# STM32N645 register map
File version: 1.0
CPU: CM55 r0p1, little endian, no MPU, FPU, vendor SysTick, 8 interrupt priority bits
Registers are 32-bit, read-write, reset 0x0 unless marked. A register's access mark holds for its fields unless they carry their own. Offsets are from the block's base; [hi:lo] are bit positions; {n}, {i} and the like mark numbered series; 'fields as' and 'values as' point back to an identical list.

## OTG1 — USB on-the-go high-speed
Base 0x48040000
Same registers: OTG2 0x48080000, OTG1_S 0x58040000, OTG2_S 0x58080000
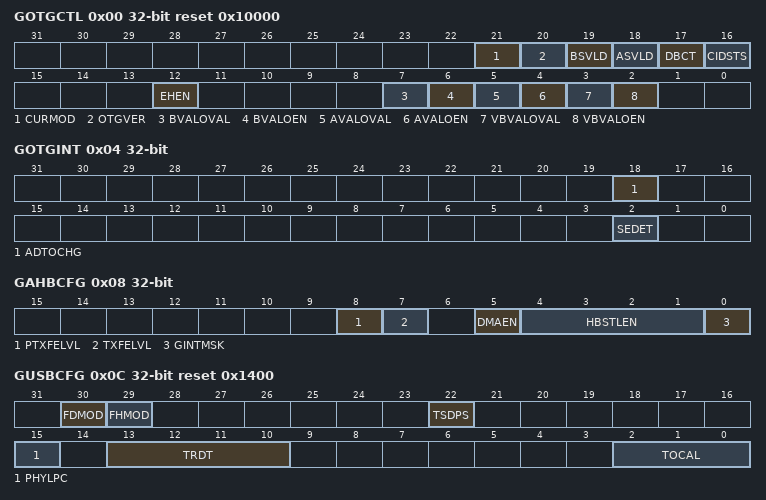
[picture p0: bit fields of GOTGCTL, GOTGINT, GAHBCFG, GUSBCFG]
0x00 GOTGCTL access per field reset 0x10000 — OTG control and status register
  [21] CURMOD ro — Current mode of operation
  [20] OTGVER rw — OTG version
  [19] BSVLD ro — B-session valid
  [18] ASVLD ro — A-session valid
  [17] DBCT ro — Long/short debounce time
  [16] CIDSTS ro — Connector ID status
  [12] EHEN rw — Embedded host enable
  [7] BVALOVAL rw — B-peripheral session valid override value.
  [6] BVALOEN rw — B-peripheral session valid override enable.
  [5] AVALOVAL rw — A-peripheral session valid override value.
  [4] AVALOEN rw — A-peripheral session valid override enable.
  [3] VBVALOVAL rw — V less than sub>BUS less than /sub> valid override value.
  [2] VBVALOEN rw — V less than sub>BUS less than /sub> valid override enable.
0x04 GOTGINT — OTG interrupt register
  [18] ADTOCHG — A-device timeout change
  [2] SEDET — Session end detected
0x08 GAHBCFG — OTG AHB configuration register
  [8] PTXFELVL — Periodic Tx FIFO empty level
  [7] TXFELVL — Tx FIFO empty level
  [5] DMAEN — DMA enabled
  [4:1] HBSTLEN — Burst length/type
  [0] GINTMSK — Global interrupt mask
0x0C GUSBCFG reset 0x1400 — OTG USB configuration register
  [30] FDMOD — Force device mode
  [29] FHMOD — Force host mode
  [22] TSDPS — TermSel DLine pulsing selection
  [15] PHYLPC — PHY Low-power clock select
  [13:10] TRDT — USB turnaround time
  [2:0] TOCAL — FS timeout calibration
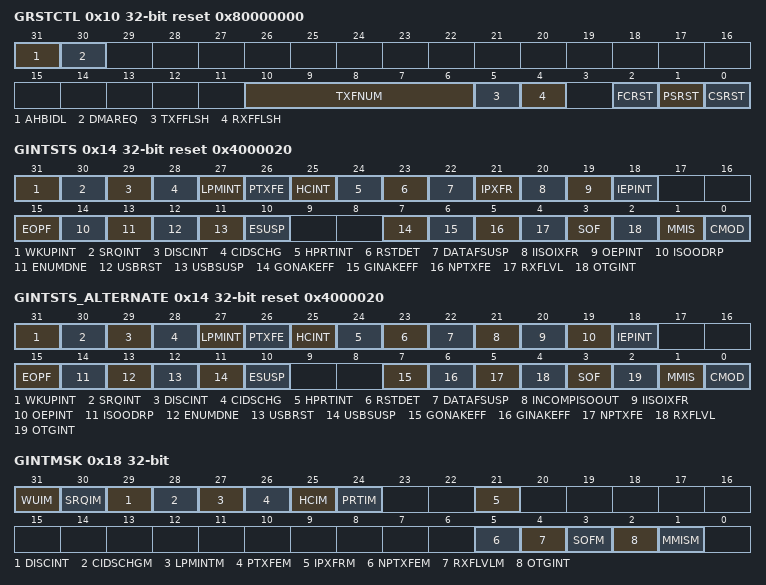
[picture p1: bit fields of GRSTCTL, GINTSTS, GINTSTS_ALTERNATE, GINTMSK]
0x10 GRSTCTL access per field reset 0x80000000 — OTG reset register
  [31] AHBIDL ro — AHB master idle
  [30] DMAREQ ro — DMA request signal enabled
  [10:6] TXFNUM rw — Tx FIFO number
  [5] TXFFLSH rw — Tx FIFO flush
  [4] RXFFLSH rw — Rx FIFO flush
  [2] FCRST rw — Host frame counter reset
  [1] PSRST rw — Partial soft reset
  [0] CSRST rw — Core soft reset
0x14 GINTSTS access per field reset 0x4000020 — OTG core interrupt register [alternate]
  [31] WKUPINT rw — Resume/remote wake-up detected interrupt
  [30] SRQINT rw — Session request/new session detected interrupt
  [29] DISCINT rw — Disconnect detected interrupt
  [28] CIDSCHG rw — Connector ID status change
  [27] LPMINT rw — LPM interrupt
  [26] PTXFE ro — Periodic Tx FIFO empty
  [25] HCINT ro — Host channels interrupt
  [24] HPRTINT ro — Host port interrupt
  [23] RSTDET rw — Reset detected interrupt
  [22] DATAFSUSP rw — Data fetch suspended
  [21] IPXFR rw — Incomplete periodic transfer
  [20] IISOIXFR rw — Incomplete isochronous IN transfer
  [19] OEPINT ro — OUT endpoint interrupt
  [18] IEPINT ro — IN endpoint interrupt
  [15] EOPF rw — End of periodic frame interrupt
  [14] ISOODRP rw — Isochronous OUT packet dropped interrupt
  [13] ENUMDNE rw — Enumeration done
  [12] USBRST rw — USB reset
  [11] USBSUSP rw — USB suspend
  [10] ESUSP rw — Early suspend
  [7] GONAKEFF ro — Global OUT NAK effective
  [6] GINAKEFF ro — Global IN non-periodic NAK effective
  [5] NPTXFE ro — Non-periodic Tx FIFO empty
  [4] RXFLVL ro — Rx FIFO non-empty
  [3] SOF rw — Start of frame
  [2] OTGINT ro — OTG interrupt
  [1] MMIS rw — Mode mismatch interrupt
  [0] CMOD ro — Current mode of operation
0x14 GINTSTS_ALTERNATE access per field reset 0x4000020 (alternate view of GINTSTS) — OTG core interrupt register [alternate]
  [31] WKUPINT rw — Resume/remote wake-up detected interrupt
  [30] SRQINT rw — Session request/new session detected interrupt
  [29] DISCINT rw — Disconnect detected interrupt
  [28] CIDSCHG rw — Connector ID status change
  [27] LPMINT rw — LPM interrupt
  [26] PTXFE ro — Periodic Tx FIFO empty
  [25] HCINT ro — Host channels interrupt
  [24] HPRTINT ro — Host port interrupt
  [23] RSTDET rw — Reset detected interrupt
  [22] DATAFSUSP rw — Data fetch suspended
  [21] INCOMPISOOUT rw — Incomplete isochronous OUT transfer
  [20] IISOIXFR rw — Incomplete isochronous IN transfer
  [19] OEPINT ro — OUT endpoint interrupt
  [18] IEPINT ro — IN endpoint interrupt
  [15] EOPF rw — End of periodic frame interrupt
  [14] ISOODRP rw — Isochronous OUT packet dropped interrupt
  [13] ENUMDNE rw — Enumeration done
  [12] USBRST rw — USB reset
  [11] USBSUSP rw — USB suspend
  [10] ESUSP rw — Early suspend
  [7] GONAKEFF ro — Global OUT NAK effective
  [6] GINAKEFF ro — Global IN non-periodic NAK effective
  [5] NPTXFE ro — Non-periodic Tx FIFO empty
  [4] RXFLVL ro — Rx FIFO non-empty
  [3] SOF rw — Start of frame
  [2] OTGINT ro — OTG interrupt
  [1] MMIS rw — Mode mismatch interrupt
  [0] CMOD ro — Current mode of operation
0x18 GINTMSK access per field — OTG interrupt mask register [alternate]
  [31] WUIM rw — Resume/remote wake-up detected interrupt mask
  [30] SRQIM rw — Session request/new session detected interrupt mask
  [29] DISCINT rw — Disconnect detected interrupt mask
  [28] CIDSCHGM rw — Connector ID status change mask
  [27] LPMINTM rw — LPM interrupt mask
  [26] PTXFEM rw — Periodic Tx FIFO empty mask
  [25] HCIM rw — Host channels interrupt mask
  [24] PRTIM ro — Host port interrupt mask
  [21] IPXFRM rw — Incomplete periodic transfer mask
  [5] NPTXFEM rw — Non-periodic Tx FIFO empty mask
  [4] RXFLVLM rw — Receive FIFO non-empty mask
  [3] SOFM rw — Start of frame mask
  [2] OTGINT rw — OTG interrupt mask
  [1] MMISM rw — Mode mismatch interrupt mask
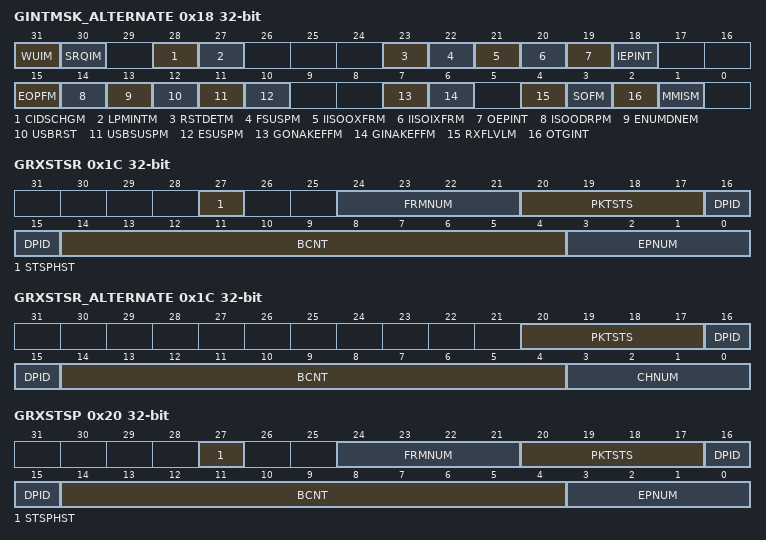
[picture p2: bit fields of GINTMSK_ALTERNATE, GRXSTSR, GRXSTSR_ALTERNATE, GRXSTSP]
0x18 GINTMSK_ALTERNATE (alternate view of GINTMSK) — OTG interrupt mask register [alternate]
  [31] WUIM — Resume/remote wake-up detected interrupt mask
  [30] SRQIM — Session request/new session detected interrupt mask
  [28] CIDSCHGM — Connector ID status change mask
  [27] LPMINTM — LPM interrupt mask
  [23] RSTDETM — Reset detected interrupt mask
  [22] FSUSPM — Data fetch suspended mask
  [21] IISOOXFRM — Incomplete isochronous OUT transfer mask
  [20] IISOIXFRM — Incomplete isochronous IN transfer mask
  [19] OEPINT — OUT endpoints interrupt mask
  [18] IEPINT — IN endpoints interrupt mask
  [15] EOPFM — End of periodic frame interrupt mask
  [14] ISOODRPM — Isochronous OUT packet dropped interrupt mask
  [13] ENUMDNEM — Enumeration done mask
  [12] USBRST — USB reset mask
  [11] USBSUSPM — USB suspend mask
  [10] ESUSPM — Early suspend mask
  [7] GONAKEFFM — Global OUT NAK effective mask
  [6] GINAKEFFM — Global non-periodic IN NAK effective mask
  [4] RXFLVLM — Receive FIFO non-empty mask
  [3] SOFM — Start of frame mask
  [2] OTGINT — OTG interrupt mask
  [1] MMISM — Mode mismatch interrupt mask
0x1C GRXSTSR ro — OTG receive status debug read register [alternate]
  [27] STSPHST — Status phase start
  [24:21] FRMNUM — Frame number
  [20:17] PKTSTS — Packet status
  [16:15] DPID — Data PID
  [14:4] BCNT — Byte count
  [3:0] EPNUM — Endpoint number
0x1C GRXSTSR_ALTERNATE ro (alternate view of GRXSTSR) — OTG receive status debug read register [alternate]
  [20:17] PKTSTS — Packet status
  [16:15] DPID — Data PID
  [14:4] BCNT — Byte count
  [3:0] CHNUM — Channel number
0x20 GRXSTSP ro — OTG status read and pop registers
  fields as GRXSTSR
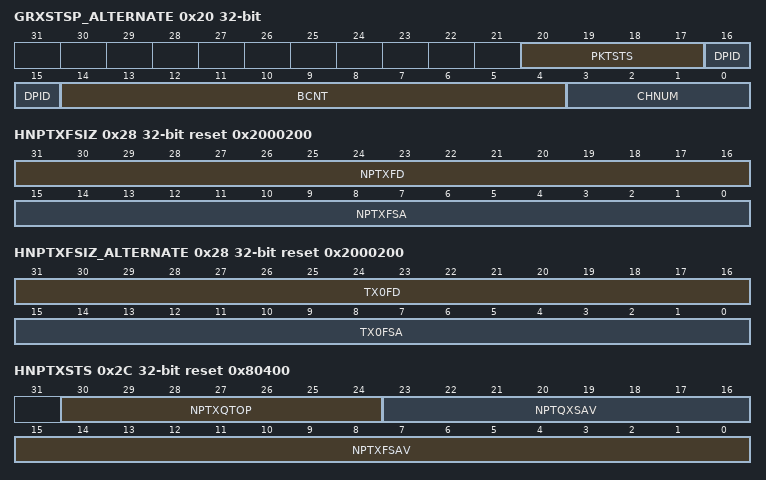
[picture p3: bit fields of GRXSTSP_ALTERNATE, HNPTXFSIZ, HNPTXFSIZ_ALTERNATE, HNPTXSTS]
0x20 GRXSTSP_ALTERNATE ro (alternate view of GRXSTSP) — OTG status read and pop registers
  fields as GRXSTSR_ALTERNATE
0x24 GRXFSIZ reset 0x400 — OTG receive FIFO size register
  [15:0] RXFD — Rx FIFO depth
0x28 HNPTXFSIZ reset 0x2000200 — OTG host non-periodic transmit FIFO size register [alternate]
  [31:16] NPTXFD — Non-periodic Tx FIFO depth
  [15:0] NPTXFSA — Non-periodic transmit RAM start address
0x28 HNPTXFSIZ_ALTERNATE reset 0x2000200 (alternate view of HNPTXFSIZ) — OTG host non-periodic transmit FIFO size register [alternate]
  [31:16] TX0FD — Endpoint 0 Tx FIFO depth
  [15:0] TX0FSA — Endpoint 0 transmit RAM start address
0x2C HNPTXSTS ro reset 0x80400 — OTG non-periodic transmit FIFO/queue status register
  [30:24] NPTXQTOP — Top of the non-periodic transmit request queue
  [23:16] NPTQXSAV — Non-periodic transmit request queue space available
  [15:0] NPTXFSAV — Non-periodic Tx FIFO space available
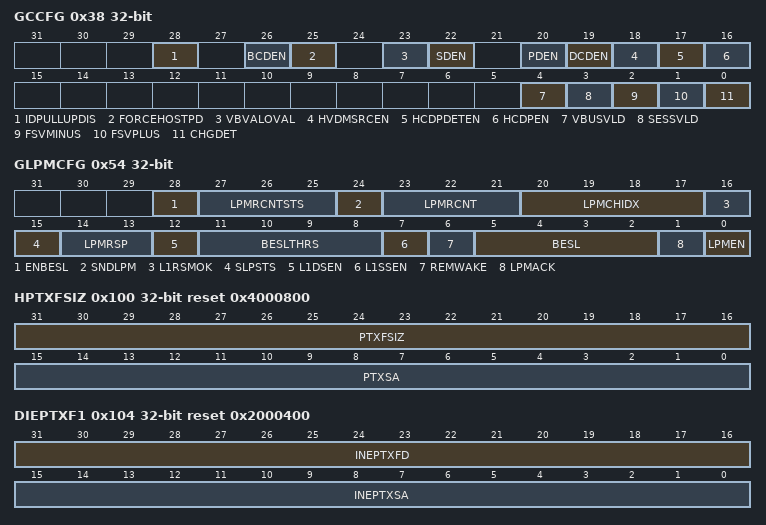
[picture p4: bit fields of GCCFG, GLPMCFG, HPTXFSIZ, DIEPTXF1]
0x38 GCCFG access per field (reset mask 0xFFFF0000) — OTG general core configuration register
  [28] IDPULLUPDIS rw — Disable ID pin pull-up
  [26] BCDEN rw — Force Battery charging (BC) mode
  [25] FORCEHOSTPD rw — Force host mode pull-downs
  [23] VBVALOVAL rw — Software override value of the VBUS B-session detection
  [22] SDEN rw — Secondary detection enable
  [20] PDEN rw — Primary detection enable
  [19] DCDEN rw — Data Contact Detection enable
  [18] HVDMSRCEN rw — Host CDP port Voltage source enable on DM
  [17] HCDPDETEN rw — Host CDP port voltage detector enable on DP
  [16] HCDPEN rw — Host CDP behavior enable
  [4] VBUSVLD ro — VBUS valid indicator
  [3] SESSVLD ro — VBUS session indicator
  [2] FSVMINUS ro — Single-Ended DM indicator
  [1] FSVPLUS ro — Single-Ended DP indicator
  [0] CHGDET ro — Charger detection, result of the current mode (primary or secondary).
0x3C CID reset 0x5000 — OTG core ID register
  [31:0] PRODUCT_ID
0x54 GLPMCFG access per field — OTG core LPM configuration register
  [28] ENBESL rw — Enable best effort service latency
  [27:25] LPMRCNTSTS ro — LPM retry count status
  [24] SNDLPM rw — Send LPM transaction
  [23:21] LPMRCNT rw — LPM retry count
  [20:17] LPMCHIDX rw — LPM Channel Index
  [16] L1RSMOK ro — Sleep state resume OK
  [15] SLPSTS ro — Port sleep status
  [14:13] LPMRSP ro — LPM response
  [12] L1DSEN rw — L1 deep sleep enable
  [11:8] BESLTHRS rw — BESL threshold
  [7] L1SSEN rw — L1 Shallow Sleep enable
  [6] REMWAKE rw — bRemoteWake value
  [5:2] BESL rw — Best effort service latency
  [1] LPMACK rw — LPM token acknowledge enable
  [0] LPMEN rw — LPM support enable
0x100 HPTXFSIZ reset 0x4000800 — OTG host periodic transmit FIFO size register
  [31:16] PTXFSIZ — Host periodic Tx FIFO depth
  [15:0] PTXSA — Host periodic Tx FIFO start address
0x104 DIEPTXF1 reset 0x2000400 — OTG device IN endpoint transmit FIFO 1 size register
  [31:16] INEPTXFD — IN endpoint Tx FIFO depth
  [15:0] INEPTXSA — IN endpoint FIFOx transmit RAM start address
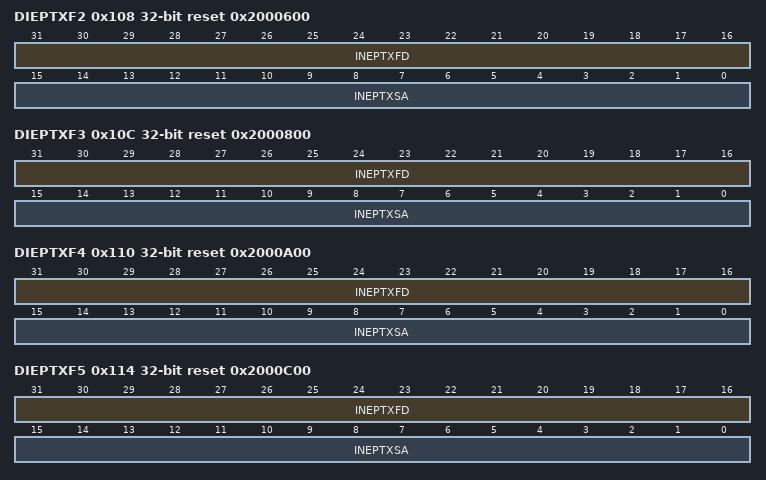
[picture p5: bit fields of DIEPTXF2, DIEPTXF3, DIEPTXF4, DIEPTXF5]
0x108 DIEPTXF2 reset 0x2000600 — OTG device IN endpoint transmit FIFO 2 size register
  fields as DIEPTXF1
0x10C DIEPTXF3 reset 0x2000800 — OTG device IN endpoint transmit FIFO 3 size register
  fields as DIEPTXF1
0x110 DIEPTXF4 reset 0x2000A00 — OTG device IN endpoint transmit FIFO 4 size register
  fields as DIEPTXF1
0x114 DIEPTXF5 reset 0x2000C00 — OTG device IN endpoint transmit FIFO 5 size register
  fields as DIEPTXF1
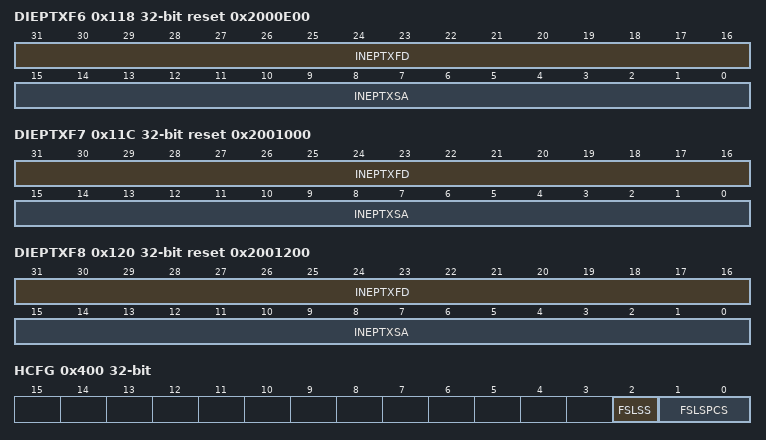
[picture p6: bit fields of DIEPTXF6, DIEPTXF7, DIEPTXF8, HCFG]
0x118 DIEPTXF6 reset 0x2000E00 — OTG device IN endpoint transmit FIFO 6 size register
  fields as DIEPTXF1
0x11C DIEPTXF7 reset 0x2001000 — OTG device IN endpoint transmit FIFO 7 size register
  fields as DIEPTXF1
0x120 DIEPTXF8 reset 0x2001200 — OTG device IN endpoint transmit FIFO 8 size register
  fields as DIEPTXF1
0x400 HCFG access per field — OTG host configuration register
  [2] FSLSS ro — FS- and LS-only support
  [1:0] FSLSPCS rw — FS/LS PHY clock select
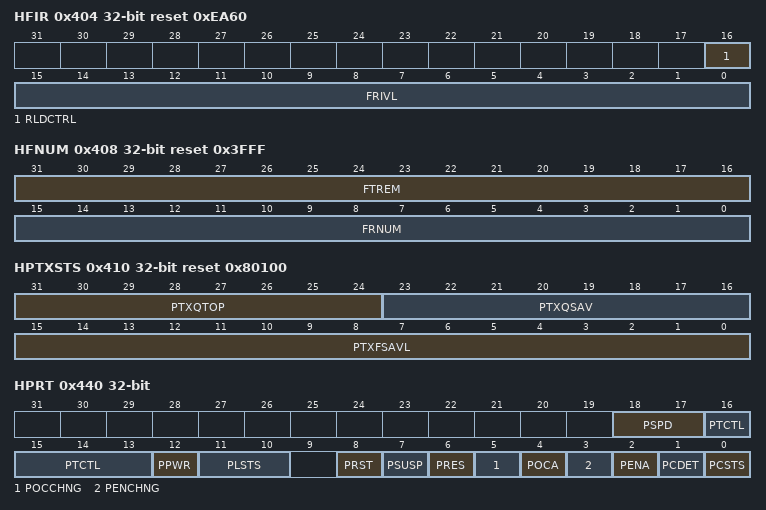
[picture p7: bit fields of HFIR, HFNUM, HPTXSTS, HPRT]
0x404 HFIR reset 0xEA60 — OTG host frame interval register
  [16] RLDCTRL — Reload control
  [15:0] FRIVL — Frame interval
0x408 HFNUM ro reset 0x3FFF — OTG host frame number/frame time remaining register
  [31:16] FTREM — Frame time remaining
  [15:0] FRNUM — Frame number
0x410 HPTXSTS ro reset 0x80100 — OTG_Host periodic transmit FIFO/queue status register
  [31:24] PTXQTOP — Top of the periodic transmit request queue
  [23:16] PTXQSAV — Periodic transmit request queue space available
  [15:0] PTXFSAVL — Periodic transmit data FIFO space available
0x414 HAINT ro — OTG host all channels interrupt register
  [15:0] HAINT — Channel interrupts
0x418 HAINTMSK — OTG host all channels interrupt mask register
  [15:0] HAINTM — Channel interrupt mask
0x440 HPRT access per field — OTG host port control and status register
  [18:17] PSPD ro — Port speed
  [16:13] PTCTL rw — Port test control
  [12] PPWR rw — Port power
  [11:10] PLSTS ro — Port line status
  [8] PRST rw — Port reset
  [7] PSUSP rw — Port suspend
  [6] PRES rw — Port resume
  [5] POCCHNG rw — Port overcurrent change
  [4] POCA ro — Port overcurrent active
  [3] PENCHNG rw — Port enable/disable change
  [2] PENA rw — Port enable
  [1] PCDET rw — Port connect detected
  [0] PCSTS ro — Port connect status
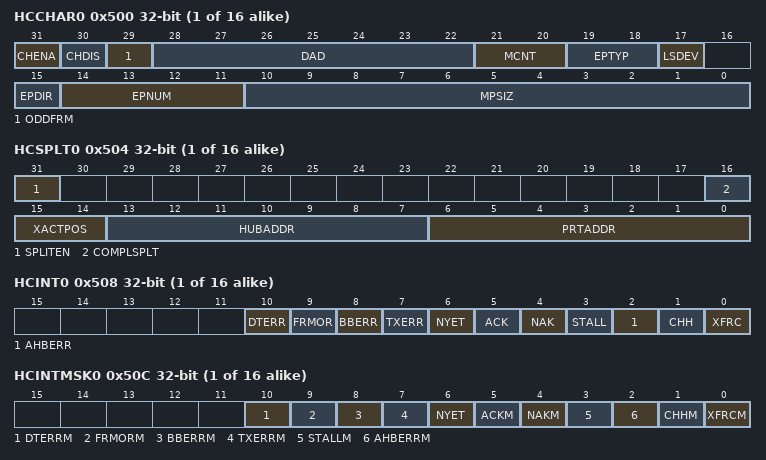
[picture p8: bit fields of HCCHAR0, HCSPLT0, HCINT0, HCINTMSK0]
{0x500+0x20*i} HCCHAR{i} (i=0..15) — OTG host channel {i} characteristics register
  [31] CHENA — Channel enable
  [30] CHDIS — Channel disable
  [29] ODDFRM — Odd frame
  [28:22] DAD — Device address
  [21:20] MCNT — Multicount
  [19:18] EPTYP — Endpoint type
  [17] LSDEV — Low-speed device
  [15] EPDIR — Endpoint direction
  [14:11] EPNUM — Endpoint number
  [10:0] MPSIZ — Maximum packet size
{0x504+0x20*i} HCSPLT{i} (i=0..15) — OTG host channel {i} split control register
  [31] SPLITEN — Split enable
  [16] COMPLSPLT — Do complete split
  [15:14] XACTPOS — Transaction position
  [13:7] HUBADDR — Hub address
  [6:0] PRTADDR — Port address
{0x508+0x20*i} HCINT{i} (i=0..15) — OTG host channel {i} interrupt register
  [10] DTERR — Data toggle error.
  [9] FRMOR — Frame overrun.
  [8] BBERR — Babble error.
  [7] TXERR — Transaction error.
  [6] NYET — Not yet ready response received interrupt.
  [5] ACK — ACK response received/transmitted interrupt.
  [4] NAK — NAK response received interrupt.
  [3] STALL — STALL response received interrupt.
  [2] AHBERR — AHB error
  [1] CHH — Channel halted.
  [0] XFRC — Transfer completed.
{0x50C+0x20*i} HCINTMSK{i} (i=0..15) — OTG host channel {i} interrupt mask register
  [10] DTERRM — Data toggle error mask.
  [9] FRMORM — Frame overrun mask.
  [8] BBERRM — Babble error mask.
  [7] TXERRM — Transaction error mask.
  [6] NYET — response received interrupt mask.
  [5] ACKM — ACK response received/transmitted interrupt mask.
  [4] NAKM — NAK response received interrupt mask.
  [3] STALLM — STALL response received interrupt mask.
  [2] AHBERRM — AHB error.
  [1] CHHM — Channel halted mask
  [0] XFRCM — Transfer completed mask
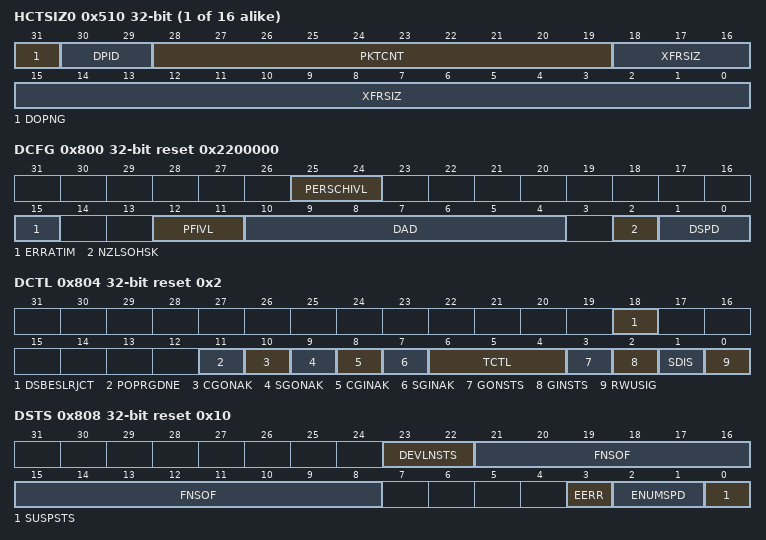
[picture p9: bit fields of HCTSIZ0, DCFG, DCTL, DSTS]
{0x510+0x20*i} HCTSIZ{i} (i=0..15) — OTG host channel {i} transfer size register
  [31] DOPNG — Do Ping
  [30:29] DPID — Data PID
  [28:19] PKTCNT — Packet count
  [18:0] XFRSIZ — Transfer size
{0x514+0x20*i} HCDMA{i} (i=0..15) — OTG host channel {i} DMA address register
  [31:0] DMAADDR — DMA address
0x800 DCFG reset 0x2200000 — OTG device configuration register
  [25:24] PERSCHIVL — Periodic schedule interval
  [15] ERRATIM — Erratic error interrupt mask
  [12:11] PFIVL — Periodic frame interval
  [10:4] DAD — Device address
  [2] NZLSOHSK — Non-zero-length status OUT handshake
  [1:0] DSPD — Device speed
0x804 DCTL access per field reset 0x2 — OTG device control register
  [18] DSBESLRJCT rw — Deep sleep BESL reject
  [11] POPRGDNE rw — Power-on programming done
  [10] CGONAK wo — Clear global OUT NAK
  [9] SGONAK wo — Set global OUT NAK
  [8] CGINAK wo — Clear global IN NAK
  [7] SGINAK wo — Set global IN NAK
  [6:4] TCTL rw — Test control
  [3] GONSTS ro — Global OUT NAK status
  [2] GINSTS ro — Global IN NAK status
  [1] SDIS rw — Soft disconnect
  [0] RWUSIG rw — Remote wake-up signaling
0x808 DSTS ro reset 0x10 — OTG device status register
  [23:22] DEVLNSTS — Device line status
  [21:8] FNSOF — Frame number of the received SOF
  [3] EERR — Erratic error
  [2:1] ENUMSPD — Enumerated speed
  [0] SUSPSTS — Suspend status
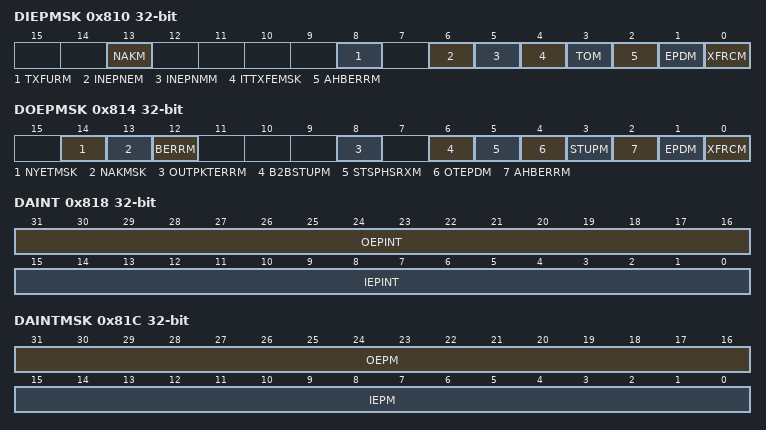
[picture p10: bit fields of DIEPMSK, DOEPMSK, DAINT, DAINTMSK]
0x810 DIEPMSK — OTG device IN endpoint common interrupt mask register
  [13] NAKM — NAK interrupt mask
  [8] TXFURM — FIFO underrun mask
  [6] INEPNEM — IN endpoint NAK effective mask
  [5] INEPNMM — IN token received with EP mismatch mask
  [4] ITTXFEMSK — IN token received when Tx FIFO empty mask
  [3] TOM — Timeout condition mask (Non-isochronous endpoints)
  [2] AHBERRM — AHB error mask
  [1] EPDM — Endpoint disabled interrupt mask
  [0] XFRCM — Transfer completed interrupt mask
0x814 DOEPMSK — OTG device OUT endpoint common interrupt mask register
  [14] NYETMSK — NYET interrupt mask
  [13] NAKMSK — NAK interrupt mask
  [12] BERRM — Babble error interrupt mask
  [8] OUTPKTERRM — Out packet error mask
  [6] B2BSTUPM — Back-to-back SETUP packets received mask
  [5] STSPHSRXM — Status phase received for control write mask
  [4] OTEPDM — OUT token received when endpoint disabled mask. Applies to control OUT endpoints only.
  [3] STUPM — STUPM: SETUP phase done mask. Applies to control endpoints only.
  [2] AHBERRM — AHB error mask
  [1] EPDM — Endpoint disabled interrupt mask
  [0] XFRCM — Transfer completed interrupt mask
0x818 DAINT ro — OTG device all endpoints interrupt register
  [31:16] OEPINT — OUT endpoint interrupt bits
  [15:0] IEPINT — IN endpoint interrupt bits
0x81C DAINTMSK — OTG all endpoints interrupt mask register
  [31:16] OEPM — OUT EP interrupt mask bits
  [15:0] IEPM — IN EP interrupt mask bits
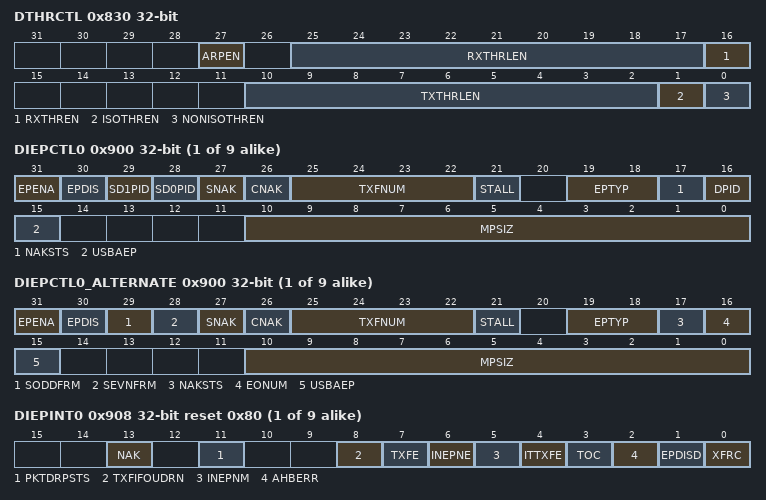
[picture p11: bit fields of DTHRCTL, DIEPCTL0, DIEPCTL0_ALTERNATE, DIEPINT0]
0x830 DTHRCTL — OTG device threshold control register
  [27] ARPEN — Arbiter parking enable
  [25:17] RXTHRLEN — Receive threshold length
  [16] RXTHREN — Receive threshold enable
  [10:2] TXTHRLEN — Transmit threshold length
  [1] ISOTHREN — ISO IN endpoint threshold enable
  [0] NONISOTHREN — Nonisochronous IN endpoints threshold enable
0x834 DIEPEMPMSK — OTG device IN endpoint FIFO empty interrupt mask register
  [15:0] INEPTXFEM — IN EP Tx FIFO empty interrupt mask bits
{0x900+0x20*i} DIEPCTL{i} access per field (i=0..8) — OTG device IN endpoint {i} control register [alternate]
  [31] EPENA rw — Endpoint enable
  [30] EPDIS rw — Endpoint disable
  [29] SD1PID wo — Set DATA1 PID
  [28] SD0PID wo — Set DATA0 PID
  [27] SNAK wo — Set NAK
  [26] CNAK wo — Clear NAK
  [25:22] TXFNUM rw — Tx FIFO number
  [21] STALL rw — STALL handshake
  [19:18] EPTYP rw — Endpoint type
  [17] NAKSTS ro — NAK status
  [16] DPID ro — Endpoint data PID
  [15] USBAEP rw — USB active endpoint
  [10:0] MPSIZ rw — Maximum packet size
{0x900+0x20*i} DIEPCTL{i}_ALTERNATE access per field (alternate view of DIEPCTL{i}) (i=0..8) — OTG device IN endpoint {i} control register [alternate]
  [31] EPENA rw — Endpoint enable
  [30] EPDIS rw — Endpoint disable
  [29] SODDFRM wo — Set odd frame
  [28] SEVNFRM wo — Set even frame
  [27] SNAK wo — Set NAK
  [26] CNAK wo — Clear NAK
  [25:22] TXFNUM rw — Tx FIFO number
  [21] STALL rw — STALL handshake
  [19:18] EPTYP rw — Endpoint type
  [17] NAKSTS ro — NAK status
  [16] EONUM ro — Even/odd frame
  [15] USBAEP rw — USB active endpoint
  [10:0] MPSIZ rw — Maximum packet size
{0x908+0x20*i} DIEPINT{i} access per field reset 0x80 (i=0..8) — OTG device IN endpoint {i} interrupt register
  [13] NAK rw — NAK input
  [11] PKTDRPSTS rw — Packet dropped status
  [8] TXFIFOUDRN rw — Transmit Fifo Underrun (TxfifoUndrn)
  [7] TXFE ro — Transmit FIFO empty
  [6] INEPNE rw — IN endpoint NAK effective
  [5] INEPNM rw — IN token received with EP mismatch
  [4] ITTXFE rw — IN token received when Tx FIFO is empty
  [3] TOC rw — Timeout condition
  [2] AHBERR rw — AHB error
  [1] EPDISD rw — Endpoint disabled interrupt
  [0] XFRC rw — Transfer completed interrupt
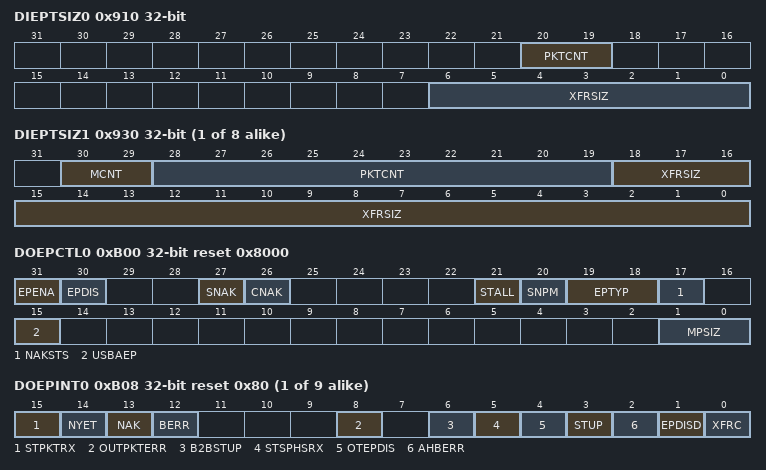
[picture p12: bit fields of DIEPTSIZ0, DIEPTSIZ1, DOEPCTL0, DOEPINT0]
0x910 DIEPTSIZ0 — OTG device IN endpoint 0 transfer size register
  [20:19] PKTCNT — Packet count
  [6:0] XFRSIZ — Transfer size
{0x914+0x20*i} DIEPDMA{i} (i=0..8) — OTG device IN endpoint {i} DMA address register
  [31:0] DMAADDR — DMA Address
{0x918+0x20*i} DTXFSTS{i} ro reset 0x200 (i=0..8) — OTG device IN endpoint transmit FIFO status register
  [15:0] INEPTFSAV — IN endpoint Tx FIFO space available
{0x910+0x20*i} DIEPTSIZ{i} (i=1..8) — OTG device IN endpoint {i} transfer size register
  [30:29] MCNT — Multi count
  [28:19] PKTCNT — Packet count
  [18:0] XFRSIZ — Transfer size
0xB00 DOEPCTL0 access per field reset 0x8000 — OTG device control OUT endpoint 0 control register
  [31] EPENA wo — Endpoint enable
  [30] EPDIS ro — Endpoint disable
  [27] SNAK wo — Set NAK
  [26] CNAK wo — Clear NAK
  [21] STALL rw — STALL handshake
  [20] SNPM rw — Snoop mode
  [19:18] EPTYP ro — Endpoint type
  [17] NAKSTS ro — NAK status
  [15] USBAEP ro — USB active endpoint
  [1:0] MPSIZ ro — Maximum packet size
{0xB08+0x20*i} DOEPINT{i} reset 0x80 (i=0..8) — OTG device OUT endpoint {i} interrupt register
  [15] STPKTRX — Setup packet received
  [14] NYET — NYET interrupt
  [13] NAK — NAK input
  [12] BERR — Babble error interrupt
  [8] OUTPKTERR — OUT packet error
  [6] B2BSTUP — Back-to-back SETUP packets received
  [5] STSPHSRX — Status phase received for control write
  [4] OTEPDIS — OUT token received when endpoint disabled
  [3] STUP — SETUP phase done
  [2] AHBERR — AHB error
  [1] EPDISD — Endpoint disabled interrupt
  [0] XFRC — Transfer completed interrupt
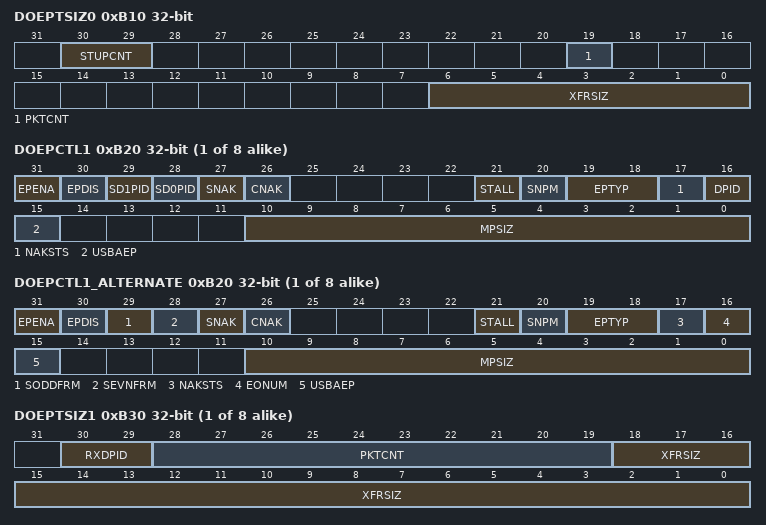
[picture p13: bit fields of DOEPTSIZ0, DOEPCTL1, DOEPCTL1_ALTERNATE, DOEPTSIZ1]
0xB10 DOEPTSIZ0 — OTG device OUT endpoint 0 transfer size register
  [30:29] STUPCNT — SETUP packet count
  [19] PKTCNT — Packet count
  [6:0] XFRSIZ — Transfer size
{0xB14+0x20*i} DOEPDMA{i} (i=0..8) — OTG device OUT endpoint {i} DMA address register
  [31:0] DMAADDR — DMA Address
{0xB00+0x20*i} DOEPCTL{i} access per field (i=1..8) — OTG device OUT endpoint {i} control register [alternate]
  [31] EPENA rw — Endpoint enable
  [30] EPDIS rw — Endpoint disable
  [29] SD1PID wo — Set DATA1 PID
  [28] SD0PID wo — Set DATA0 PID
  [27] SNAK wo — Set NAK
  [26] CNAK wo — Clear NAK
  [21] STALL rw — STALL handshake
  [20] SNPM rw — Snoop mode
  [19:18] EPTYP rw — Endpoint type
  [17] NAKSTS ro — NAK status
  [16] DPID ro — Endpoint data PID
  [15] USBAEP rw — USB active endpoint
  [10:0] MPSIZ rw — Maximum packet size
{0xB00+0x20*i} DOEPCTL{i}_ALTERNATE access per field (alternate view of DOEPCTL{i}) (i=1..8) — OTG device OUT endpoint {i} control register [alternate]
  [31] EPENA rw — Endpoint enable
  [30] EPDIS rw — Endpoint disable
  [29] SODDFRM wo — Set odd frame
  [28] SEVNFRM wo — Set even frame
  [27] SNAK wo — Set NAK
  [26] CNAK wo — Clear NAK
  [21] STALL rw — STALL handshake
  [20] SNPM rw — Snoop mode
  [19:18] EPTYP rw — Endpoint type
  [17] NAKSTS ro — NAK status
  [16] EONUM ro — Even/odd frame
  [15] USBAEP rw — USB active endpoint
  [10:0] MPSIZ rw — Maximum packet size
{0xB10+0x20*i} DOEPTSIZ{i} (i=1..8) — OTG device OUT endpoint {i} transfer size register
  [30:29] RXDPID — Received data PID
  [28:19] PKTCNT — Packet count
  [18:0] XFRSIZ — Transfer size
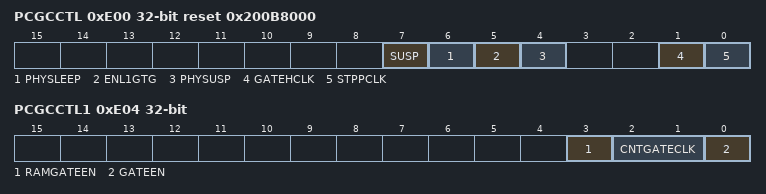
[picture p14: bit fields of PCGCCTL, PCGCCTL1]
0xE00 PCGCCTL access per field reset 0x200B8000 — OTG power and clock gating control register
  [7] SUSP ro — Deep Sleep
  [6] PHYSLEEP ro — PHY in Sleep
  [5] ENL1GTG rw — Enable sleep clock gating
  [4] PHYSUSP ro — PHY suspended
  [1] GATEHCLK rw
  [0] STPPCLK rw — Stop PHY clock
0xE04 PCGCCTL1 — OTG power and clock gating control register 1
  [3] RAMGATEEN — Enable RAM clock gating
  [2:1] CNTGATECLK — Counter for clock gating
  [0] GATEEN — Enable active clock gating
